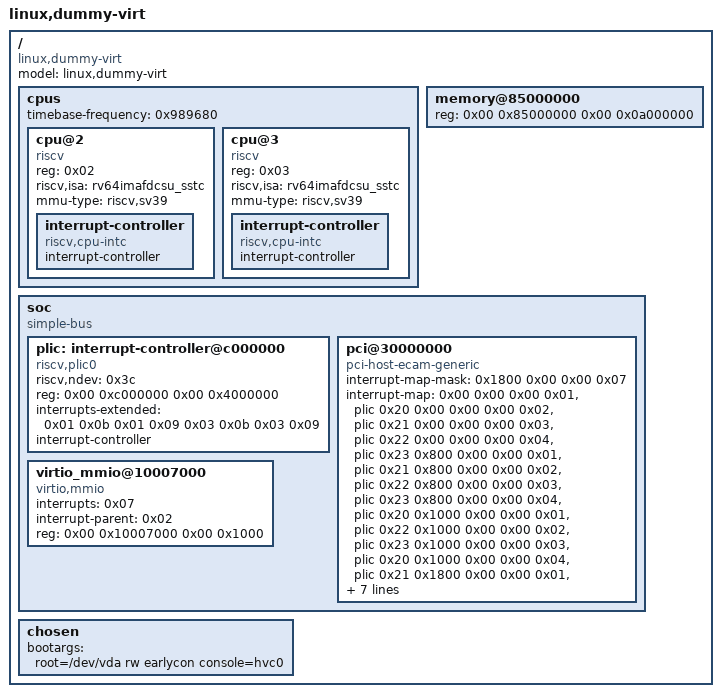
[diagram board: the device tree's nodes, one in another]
/dts-v1/;

/ {
	model = "linux,dummy-virt";
	compatible = "linux,dummy-virt";
	#address-cells = <0x02>;
	#size-cells = <0x02>;

	cpus {
		#address-cells = <0x01>;
		#size-cells = <0x00>;
		timebase-frequency = <0x989680>;

		cpu@2 {
			device_type = "cpu";
			reg = <0x02>;
			status = "okay";
			compatible = "riscv";
			riscv,isa = "rv64imafdcsu_sstc";
			mmu-type = "riscv,sv39";

			interrupt-controller {
				#interrupt-cells = <0x01>;
				interrupt-controller;
				compatible = "riscv,cpu-intc";
				phandle = <0x01>;
			};
		};

		cpu@3 {
			device_type = "cpu";
			reg = <0x03>;
			status = "okay";
			compatible = "riscv";
			riscv,isa = "rv64imafdcsu_sstc";
			mmu-type = "riscv,sv39";

			interrupt-controller {
				#interrupt-cells = <0x01>;
				interrupt-controller;
				compatible = "riscv,cpu-intc";
				phandle = <0x03>;
			};
		};
	};

	memory@85000000 {
		device_type = "memory";
		reg = <0x00 0x85000000 0x00 0x0a000000>;
	};

	soc {
		#address-cells = <0x02>;
		#size-cells = <0x02>;
		compatible = "simple-bus";
		ranges;

		plic: interrupt-controller@c000000 {
			riscv,ndev = <0x3c>;
			reg = <0x00 0xc000000 0x00 0x4000000>;
			interrupts-extended = <0x01 0x0b 0x01 0x09 0x03 0x0b 0x03 0x09>;
			interrupt-controller;
			compatible = "riscv,plic0";
			#interrupt-cells = <0x01>;
			phandle = <0x02>;
		};

		pci@30000000 {
			interrupt-map-mask = <0x1800 0x00 0x00 0x07>;
			interrupt-map = <0x00 0x00 0x00 0x01 &plic 0x20
			0x00 0x00 0x00 0x02 &plic 0x21
			0x00 0x00 0x00 0x03 &plic 0x22
			0x00 0x00 0x00 0x04 &plic 0x23 
			0x800 0x00 0x00 0x01 &plic 0x21
			0x800 0x00 0x00 0x02 &plic 0x22
			0x800 0x00 0x00 0x03 &plic 0x23
			0x800 0x00 0x00 0x04 &plic 0x20
			0x1000 0x00 0x00 0x01 &plic 0x22
			0x1000 0x00 0x00 0x02 &plic 0x23
			0x1000 0x00 0x00 0x03 &plic 0x20
			0x1000 0x00 0x00 0x04 &plic 0x21
			0x1800 0x00 0x00 0x01 &plic 0x23
			0x1800 0x00 0x00 0x02 &plic 0x20
			0x1800 0x00 0x00 0x03 &plic 0x21
			0x1800 0x00 0x00 0x04 &plic 0x22>;
			ranges = <0x1000000 0x00 0x00 0x00 0x3000000 0x00 0x10000
			0x2000000 0x00 0x40000000 0x00 0x40000000 0x00 0x40000000
			0x3000000 0x04 0x00 0x04 0x00 0x04 0x00>;
			reg = <0x00 0x30000000 0x00 0x10000000>;
			dma-coherent;
			bus-range = <0x00 0xff>;
			linux,pci-domain = <0x00>;
			device_type = "pci";
			compatible = "pci-host-ecam-generic";
			#size-cells = <0x02>;
			#interrupt-cells = <0x01>;
			#address-cells = <0x03>;
		};

		virtio_mmio@10007000 {
			interrupts = <0x07>;
			interrupt-parent = <0x02>;
			reg = <0x00 0x10007000 0x00 0x1000>;
			compatible = "virtio,mmio";
		};
	};

	chosen {
		bootargs = "root=/dev/vda rw earlycon console=hvc0";
	};
};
